VERSION ""

NS_ :

BS_:

BU_:

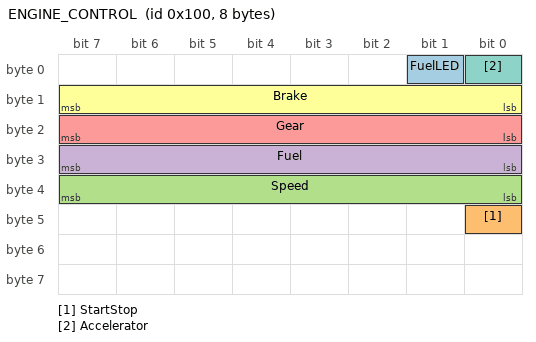
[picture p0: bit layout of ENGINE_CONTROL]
BO_ 256 ENGINE_CONTROL: 8 Vector__XXX
 SG_ FuelLED : 1|1@1+ (1,0) [0|1] "" Vector__XXX
 SG_ StartStop : 40|1@1+ (1,0) [0|1] "" Vector__XXX
 SG_ Speed : 32|8@1+ (1,0) [0|255] "" Vector__XXX
 SG_ Fuel : 24|8@1+ (1,0) [0|100] "" Vector__XXX
 SG_ Gear : 16|8@1+ (1,0) [0|255] "" Vector__XXX
 SG_ Brake : 8|8@1+ (1,0) [0|255] "" Vector__XXX
 SG_ Accelerator : 0|1@1+ (1,0) [0|1] "" Vector__XXX

EV_ SignDisplay: 0 [0|0] "" 0 1 DUMMY_NODE_VECTOR8000 Vector__XXX;

BA_DEF_  "BusType" STRING ;
BA_DEF_DEF_  "BusType" "CAN";
